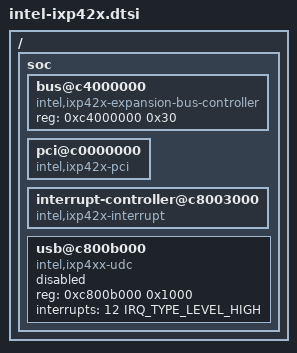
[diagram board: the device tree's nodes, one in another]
#include "intel-ixp4xx.dtsi"
/ {
	soc {
		bus@c4000000 {
			compatible = "intel,ixp42x-expansion-bus-controller", "syscon";
			reg = <0xc4000000 0x30>;
		};
		pci@c0000000 {
			compatible = "intel,ixp42x-pci";
		};
		interrupt-controller@c8003000 {
			compatible = "intel,ixp42x-interrupt";
		};
		usb@c800b000 {
			compatible = "intel,ixp4xx-udc";
			reg = <0xc800b000 0x1000>;
			interrupts = <12 IRQ_TYPE_LEVEL_HIGH>;
			status = "disabled";
		};
	};
};
